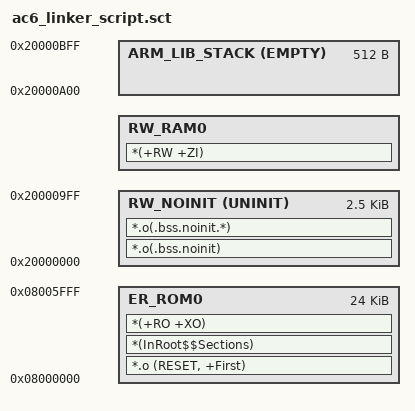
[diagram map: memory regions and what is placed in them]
# 1 "/home/kfujii/\343\203\211\343\202\255\343\203\245\343\203\241\343\203\263\343\203\210/KeilStudio/PY32F002B/CLOCK_SOURCE/CLOCK_SOURCE/RTE/Device/PY32F002Bx5/ac6_linker_script.sct.src"
# 1 "<built-in>" 1
# 1 "<built-in>" 3
# 392 "<built-in>" 3
# 1 "<command line>" 1
# 1 "<built-in>" 2
# 1 "/home/kfujii/\343\203\211\343\202\255\343\203\245\343\203\241\343\203\263\343\203\210/KeilStudio/PY32F002B/CLOCK_SOURCE/CLOCK_SOURCE/RTE/Device/PY32F002Bx5/regions_PY32F002Bx5.h" 1
# 2 "<built-in>" 2
# 1 "/home/kfujii/\343\203\211\343\202\255\343\203\245\343\203\241\343\203\263\343\203\210/KeilStudio/PY32F002B/CLOCK_SOURCE/CLOCK_SOURCE/RTE/Device/PY32F002Bx5/ac6_linker_script.sct.src" 2
# 32 "/home/kfujii/\343\203\211\343\202\255\343\203\245\343\203\241\343\203\263\343\203\210/KeilStudio/PY32F002B/CLOCK_SOURCE/CLOCK_SOURCE/RTE/Device/PY32F002Bx5/ac6_linker_script.sct.src"
LR_ROM0 0x08000000 0x00006000 {

  ER_ROM0 0x08000000 0x00006000 {
    *.o (RESET, +First)
    *(InRoot$$Sections)
    *(+RO +XO)
  }







  RW_NOINIT 0x20000000 UNINIT (0x00000C00 - 0x00000000 - 0x00000200 - 0) {
    *.o(.bss.noinit)
    *.o(.bss.noinit.*)
  }

  RW_RAM0 AlignExpr(+0, 8) (0x00000C00 - 0x00000000 - 0x00000200 - 0 - AlignExpr(ImageLength(RW_NOINIT), 8)) {
    *(+RW +ZI)
  }






  ARM_LIB_STACK (0x20000000 + 0x00000C00 - 0) EMPTY -0x00000200 { ; Reserve empty region for stack
  }
# 85 "/home/kfujii/\343\203\211\343\202\255\343\203\245\343\203\241\343\203\263\343\203\210/KeilStudio/PY32F002B/CLOCK_SOURCE/CLOCK_SOURCE/RTE/Device/PY32F002Bx5/ac6_linker_script.sct.src"
}
